# DA14682 register map
Vendor: Dialog; Series: DA14682; File version: 1.2
CPU: CM0 r1p0, little endian, MPU, FPU, 3 interrupt priority bits
Registers are 16-bit, read-write, reset 0x0 unless marked. A register's access mark holds for its fields unless they carry their own. Offsets are from the block's base; [hi:lo] are bit positions.

## TIMER1 — TIMER1 registers
Base 0x50000200
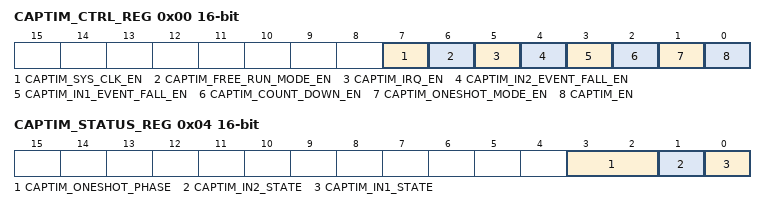
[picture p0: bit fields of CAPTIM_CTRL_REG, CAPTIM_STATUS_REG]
0x00 CAPTIM_CTRL_REG — Capture Timer control register
  [7] CAPTIM_SYS_CLK_EN — '1' Capture Timer uses the system clock '0' Capture Timer uses the 32KHz clock
  [6] CAPTIM_FREE_RUN_MODE_EN — Valid when timer counts up, if it is '1' timer does not zero when reaches to reload value. it becomes zero only when it reaches the max value.
  [5] CAPTIM_IRQ_EN — '1' Capture timer IRQ is unmasked, '0' masked
  [4] CAPTIM_IN2_EVENT_FALL_EN — '1' input1 event type is falling edge, '0' rising edge
  [3] CAPTIM_IN1_EVENT_FALL_EN — '1' input2 event type is falling edge, '0' rising edge
  [2] CAPTIM_COUNT_DOWN_EN — '1' timer counts down, '0' count up
  [1] CAPTIM_ONESHOT_MODE_EN — '1' OneShot mode enabled, '0' Capture/Timer mode enabled
  [0] CAPTIM_EN — '1' Capture Timer enabled, else disabled
0x02 CAPTIM_TIMER_VAL_REG — Capture Timer counter value
  [15:0] CAPTIM_TIMER_VALUE ro — Gives the current timer value
0x04 CAPTIM_STATUS_REG — Capture Timer status register
  [3:2] CAPTIM_ONESHOT_PHASE ro — 0 : Wait for event, 1 : Delay phase, 2 : Start Shot, 3 : Shot phase
  [1] CAPTIM_IN2_STATE ro — Gives the logic level of the IN1
  [0] CAPTIM_IN1_STATE ro — Gives the logic level of the IN2
0x06 CAPTIM_GPIO1_CONF_REG — Capture Timer gpio1 selection
  [5:0] CAPTIM_GPIO1_CONF — Select one of the 37 GPIOs as IN1, Valid value 0-37. 1 for P00 .. 37 for P47. 0 Disable input
0x08 CAPTIM_GPIO2_CONF_REG — Capture Timer gpio2 selection
  [5:0] CAPTIM_GPIO2_CONF — Select one of the 37 GPIOs as IN2, Valid value 0-37. 1 for P00 .. 37 for P47. 0 Disable input
0x0A CAPTIM_RELOAD_REG — Capture Timer reload value and Delay in shot mode
  [15:0] CAPTIM_RELOAD — Reload or max value in timer mode, Delay phase duration in oneshot mode. Actual delay is the register value plus synchronization time (3 clock cycles)
0x0C CAPTIM_SHOTWIDTH_REG — Capture Timer Shot duration in shot mode
  [15:0] CAPTIM_SHOTWIDTH — Shot phase duration in oneshot mode
0x0E CAPTIM_PRESCALER_REG — Capture Timer prescaler value
  [15:0] CAPTIM_PRESCALER — Defines the timer count frequncy. CLOCK frequency / (CAPTIM_PRESCARLER+1)
0x10 CAPTIM_CAPTURE_GPIO1_REG — Capture Timer value for event on GPIO1
  [15:0] CAPTIM_CAPTURE_GPIO1 ro — Gives the Capture time for event on GPIO1
0x12 CAPTIM_CAPTURE_GPIO2_REG — Capture Timer value for event on GPIO2
  [15:0] CAPTIM_CAPTURE_GPIO2 ro — Gives the Capture time for event on GPIO2
0x14 CAPTIM_PRESCALER_VAL_REG — Capture Timer interrupt status register
  [15:0] CAPTIM_PRESCALER_VAL ro — Gives the current prescaler value
0x16 CAPTIM_PWM_FREQ_REG — Capture Timer pwm frequency register
  [15:0] CAPTIM_PWM_FREQ — Defines the PWM frequency. Timer clock frequency / (CAPTIM_PWM_FREQ+1)
0x18 CAPTIM_PWM_DC_REG — Capture Timer pwm dc register
  [15:0] CAPTIM_PWM_DC — Defines the PWM duty cycle. CAPTIM_PWM_DC / ( CAPTIM_PWM_FREQ+1)
0x1A CAPTIM_TIMER_HVAL_REG — Capture Timer counter high value
  [15:0] CAPTIM_TIMER_HVALUE ro — Gives the current timer high value
0x1C CAPTIM_RELOAD_HIGH_REG — Capture Timer reload high value and Delay in shot mode
  [15:0] CAPTIM_RELOAD_HIGH — Reload high value or max high value in timer mode, Delay phase duration in oneshot mode. Actual delay is the register value plus synchronization time (3 clock cycles)
0x1E CAPTIM_CAPTURE_HIGH_GPIO1_REG — Capture Timer high value for event on GPIO01
  [15:0] CAPTIM_CAPTURE_HIGH_GPIO1 ro — Gives the Capture high time for event on GPIO1
0x20 CAPTIM_CAPTURE_HIGH_GPIO2_REG — Capture Timer high value for event on GPIO02
  [15:0] CAPTIM_CAPTURE_HIGH_GPIO2 ro — Gives the Capture high time for event on GPIO2
0x22 CAPTIM_SHOTWIDTH_HIGH_REG — Capture Timer Shot high duration in shot mode
  [15:0] CAPTIM_SHOTWIDTH_HIGH — Shot phase high duration in oneshot mode
